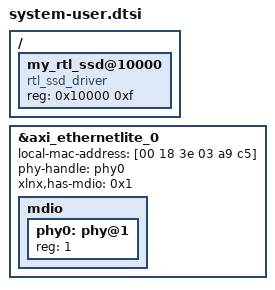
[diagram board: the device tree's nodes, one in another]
/include/ "system-conf.dtsi"
/ {
  my_rtl_ssd@10000 {
    compatible = "rtl_ssd_driver";
    reg = <0x10000 0xf>;
  };
};

&axi_ethernetlite_0 {
  local-mac-address = [00 18 3e 03 a9 c5];
  phy-handle = <&phy0>;
  xlnx,has-mdio = <0x1>;
  mdio {
    #address-cells = <1>;
    #size-cells = <0>;
    phy0: phy@1 {
      device_type = "ethernet-phy";
      reg = <1>;
    };
  };
};
